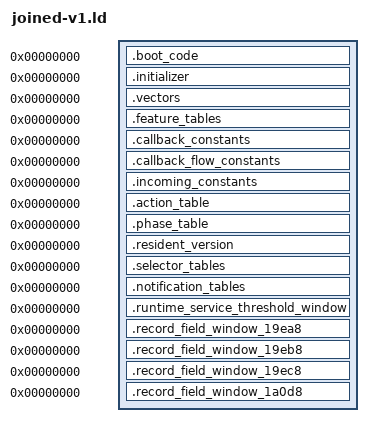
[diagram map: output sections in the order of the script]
OUTPUT_ARCH(riscv)
SECTIONS
{
 .boot_code 0 : SUBALIGN(2) { *(.boot_code)
  *(.text.tsl9_record_field_transitions_provider_8248)
  *(.text.tsl9_record_field_helpers_block_8250)
  *(.text.tsl9_record_field_helpers_block_8254)
  *(.text.tsl9_record_field_helpers_block_8256)
  *(.text.tsl9_record_field_helpers_block_8268)
  *(.text.tsl9_record_field_helpers_block_826e)
  *(.text.tsl9_record_field_helpers_block_827a)
  *(.text.tsl9_record_field_helpers_block_827c)
  *(.text.tsl9_record_field_helpers_block_8282)
  *(.text.tsl9_record_field_helpers_block_828a)
  *(.text.tsl9_record_field_transitions_provider_a476)
  *(.text.tsl9_record_field_helpers_block_a486)
  *(.text.tsl9_record_field_helpers_block_a490)
  *(.text.tsl9_record_field_helpers_block_a49c)
  *(.text.tsl9_record_field_helpers_block_a4a4)
  *(.text.tsl9_record_field_helpers_block_a4a8)
  *(.text.tsl9_record_field_helpers_block_a4ae)
  *(.text.tsl9_record_field_helpers_block_a4b2)
  *(.text.tsl9_record_field_helpers_block_a4b8)
  *(.text.tsl9_record_field_helpers_block_a4ba)
  *(.text.tsl9_record_field_helpers_block_a4c0)
  *(.text.tsl9_record_field_helpers_block_a4c6)
  *(.text.tsl9_record_field_helpers_block_a4ca)
  *(.text.tsl9_record_field_transitions_provider_a4ee)
  *(.text.tsl9_record_field_helpers_block_a504)
  *(.text.tsl9_record_field_helpers_block_a50a)
  *(.text.tsl9_record_field_helpers_block_a50c)
  *(.text.tsl9_record_field_helpers_block_a520)
  *(.text.tsl9_record_field_helpers_block_a532)
  *(.text.tsl9_record_field_helpers_block_a534)
  *(.text.tsl9_record_field_helpers_block_a53e)
  *(.text.tsl9_record_field_helpers_block_a544)
  *(.text.tsl9_record_field_helpers_block_a55a)
  *(.text.tsl9_record_field_helpers_block_a56e)
  *(.text.tsl9_record_field_helpers_block_a586)
  *(.text.tsl9_record_field_helpers_block_a592)
  *(.text.tsl9_record_field_helpers_block_a594)
  *(.text.tsl9_record_field_helpers_block_a59a)
  *(.text.tsl9_record_field_helpers_block_a5a4)
  *(.text.tsl9_record_field_helpers_block_a5b0)
  *(.text.tsl9_record_field_helpers_block_a5b6)
  *(.text.tsl9_record_field_helpers_block_a5ba)
  *(.text.tsl9_record_field_helpers_block_a5bc)
  *(.text.tsl9_record_field_helpers_block_a5d6)
  *(.text.tsl9_record_field_helpers_block_a5e4)
  *(.text.tsl9_record_field_helpers_block_a602)
  *(.text.tsl9_record_field_helpers_block_a610)
  *(.text.tsl9_record_field_helpers_block_a612)
  *(.text.tsl9_record_field_helpers_block_a614)
  *(.text.tsl9_record_field_helpers_block_a64e)
  *(.text.tsl9_record_field_transitions_provider_c7e8)
  *(.text.tsl9_record_field_helpers_block_c7f2)
  *(.text.tsl9_record_field_helpers_block_c80c)
  *(.text.tsl9_record_field_helpers_block_c810)
  *(.text.tsl9_record_field_helpers_block_c82c)
  *(.text.tsl9_record_field_helpers_block_c830)
  *(.text.tsl9_record_field_helpers_block_c832)
  *(.text.tsl9_record_field_helpers_block_c83c)
  *(.text.tsl9_record_field_helpers_block_c842)
  *(.text.tsl9_record_field_helpers_block_c84c)
  *(.text.tsl9_record_field_helpers_block_c852)
  *(.text.tsl9_record_field_helpers_block_c856)
  *(.text.tsl9_record_field_helpers_block_c860)
  *(.text.tsl9_record_field_helpers_block_c862)
  *(.text.tsl9_record_field_helpers_block_c874)
  *(.text.tsl9_record_field_helpers_block_c884)
  *(.text.tsl9_record_field_helpers_block_c888)
  *(.text.tsl9_record_field_helpers_block_c88a)
  *(.text.tsl9_record_field_helpers_block_c896)
  *(.text.tsl9_record_field_helpers_block_c89e)
  *(.text.tsl9_feature_external_cd4e)
  *(.text.tsl9_record_field_helpers_entry_cd58)
  *(.text.tsl9_record_field_transitions_provider_ed36)
  *(.text.tsl9_record_field_helpers_block_ed46)
  *(.text.tsl9_record_field_helpers_block_ed4e)
  *(.text.tsl9_record_field_helpers_block_ed5c)
  *(.text.tsl9_record_field_helpers_block_ed5e)
  *(.text.tsl9_record_field_helpers_block_ed6a)
  *(.text.tsl9_record_field_helpers_block_ed6c)
  *(.text.tsl9_record_field_helpers_block_ed70)
  *(.text.tsl9_record_field_helpers_block_ed78)
  *(.text.tsl9_record_field_helpers_block_ed82)
  *(.text.tsl9_record_field_helpers_block_ed9c)
  *(.text.tsl9_record_field_helpers_block_eda2)
  *(.text.tsl9_record_field_helpers_block_eda4)
  *(.text.tsl9_record_field_helpers_block_eda6)
  *(.text.tsl9_record_field_helpers_block_edae)
  *(.text.tsl9_record_field_helpers_block_edc2)
  *(.text.tsl9_record_field_helpers_block_edc4)
  *(.text.tsl9_record_field_helpers_block_edcc)
  *(.text.tsl9_record_field_helpers_block_edda)
  *(.text.tsl9_record_field_helpers_block_ede0)
  *(.text.tsl9_record_field_helpers_block_ede4)
  *(.text.tsl9_record_field_helpers_block_edea)
  *(.text.tsl9_record_field_helpers_block_edec)
  *(.text.tsl9_record_field_transitions_provider_f414)
  *(.text.tsl9_record_field_helpers_block_f41e)
  *(.text.tsl9_record_field_helpers_block_f43a)
  *(.text.tsl9_record_field_helpers_block_f450)
  *(.text.tsl9_record_field_helpers_block_f454)
  *(.text.tsl9_record_field_helpers_entry_f468)
  *(.text.tsl9_record_field_transitions_provider_1040e)
  *(.text.tsl9_record_field_helpers_block_1041a)
  *(.text.tsl9_record_field_helpers_block_1041c)
  *(.text.tsl9_record_field_helpers_block_10420)
  *(.text.tsl9_record_field_helpers_block_10426)
  *(.text.tsl9_record_field_helpers_block_1042a)
  *(.text.tsl9_record_field_helpers_block_1042c)
  *(.text.tsl9_record_field_helpers_block_10438)
  *(.text.tsl9_record_field_transitions_provider_12ad0)
  *(.text.tsl9_record_field_helpers_block_12ada)
  *(.text.tsl9_record_field_helpers_block_12adc)
  *(.text.tsl9_record_field_helpers_block_12ae2)
  *(.text.tsl9_record_field_helpers_block_12ae8)
  *(.text.tsl9_record_field_helpers_block_12aec)
  *(.text.tsl9_record_field_helpers_block_12aee)
  *(.text.tsl9_record_field_helpers_block_12b00)
  *(.text.tsl9_record_field_helpers_block_12b04)
  *(.text.tsl9_record_field_helpers_block_12b0a)
  *(.text.tsl9_record_field_helpers_block_12b0c)
  *(.text.tsl9_record_field_helpers_block_12b1e)
  *(.text.tsl9_record_field_transitions_provider_179fc)
  *(.text.tsl9_record_field_helpers_block_17a1c)
  *(.text.tsl9_record_field_helpers_block_17a28)
  *(.text.tsl9_record_field_helpers_block_17a2c)
  *(.text.tsl9_record_field_helpers_block_17a2e)
  *(.text.tsl9_record_field_helpers_block_17a32)
  *(.text.tsl9_record_field_helpers_block_17a34)
  *(.text.tsl9_record_field_helpers_block_17a38)
  *(.text.tsl9_record_field_helpers_block_17a54)
  *(.text.tsl9_record_field_helpers_block_17a56)
  *(.text.tsl9_record_field_helpers_block_17a5a)
  *(.text.tsl9_record_field_helpers_block_17a66)
  *(.text.tsl9_record_field_helpers_block_17a68)
  *(.text.tsl9_record_field_helpers_block_17a6e)
  *(.text.tsl9_record_field_helpers_block_17a72)
  *(.text.tsl9_record_field_helpers_block_17a80)
  *(.text.tsl9_record_field_helpers_block_17a84)
  *(.text.tsl9_record_field_helpers_block_17a8a)
  *(.text.tsl9_record_field_helpers_block_17a96)
  *(.text.tsl9_record_field_helpers_block_17aa2)
  *(.text.tsl9_record_field_helpers_block_17ab4)
  *(.text.tsl9_record_field_helpers_block_17abc)
  *(.text.tsl9_record_field_helpers_block_17ace)
  *(.text.tsl9_record_field_helpers_block_17ad0)
  *(.text.tsl9_record_field_helpers_block_17ad6)
  *(.text.tsl9_record_field_helpers_block_17ae6)
  *(.text.tsl9_record_field_helpers_block_17af0)
  *(.text.tsl9_record_field_helpers_block_17af4)
  *(.text.tsl9_record_field_helpers_block_17af8)
  *(.text.tsl9_record_field_helpers_block_17afe)
  *(.text.tsl9_record_field_helpers_block_17b24)
  *(.text.tsl9_record_field_helpers_block_17b32)
  *(.text.tsl9_record_field_helpers_block_17b38)
  *(.text.tsl9_record_field_helpers_block_17b3c)
  *(.text.tsl9_record_field_helpers_block_17b3e)
  *(.text.tsl9_record_field_helpers_block_17b44)
  *(.text.tsl9_record_field_helpers_block_17b4a)
  *(.text.tsl9_record_field_helpers_block_17b6c)
  *(.text.tsl9_record_field_helpers_block_17b7a)
  *(.text.tsl9_record_field_helpers_block_17b82)
  *(.text.tsl9_record_field_helpers_block_17b86)
  *(.text.tsl9_record_field_helpers_block_17b8a)
 }
 .initializer 0 : SUBALIGN(4) { *(.initializer) }
 .vectors 0 : SUBALIGN(4) { *(.vectors) }
 .feature_tables 0 : SUBALIGN(4) { *(.feature_tables) }
 .callback_constants 0 : SUBALIGN(4) { *(.callback_constants) }
 .callback_flow_constants 0 : SUBALIGN(4) { *(.callback_flow_constants) }
 .incoming_constants 0 : SUBALIGN(4) { *(.incoming_constants) }
 .action_table 0 : SUBALIGN(4) { *(.action_table) }
 .phase_table 0 : SUBALIGN(4) { *(.phase_table) }
 .resident_version 0 : SUBALIGN(4) { *(.resident_version) }
 .selector_tables 0 : SUBALIGN(1) {
  *(.rodata.tsl9_feature_state_records_static_data_1a4e4)
  *(.rodata.tsl9_feature_state_records_static_data_1a518)
  *(.rodata.tsl9_feature_state_records_static_data_1a528)
  *(.rodata.tsl9_feature_state_records_static_data_1a538)
 }
 .notification_tables 0 : SUBALIGN(4) {
  *(.rodata.tsl9_selector_notifications_table_1a13c)
  *(.rodata.tsl9_selector_notifications_table_1a150)
  *(.rodata.tsl9_selector_notifications_table_1a1c8)
  *(.rodata.tsl9_selector_notifications_table_1a314)
  *(.rodata.tsl9_selector_notifications_table_1a33c)
 }
 .runtime_service_threshold_window 0 : SUBALIGN(1) { *(.runtime_service_threshold_window) }
 .record_field_window_19ea8 0 : SUBALIGN(1) { *(.record_field_window_19ea8) }
 .record_field_window_19eb8 0 : SUBALIGN(1) { *(.record_field_window_19eb8) }
 .record_field_window_19ec8 0 : SUBALIGN(1) { *(.record_field_window_19ec8) }
 .record_field_window_1a0d8 0 : SUBALIGN(1) { *(.record_field_window_1a0d8) }
 /DISCARD/ : { *(.comment) *(.riscv.attributes) *(.llvm_addrsig) }
}
